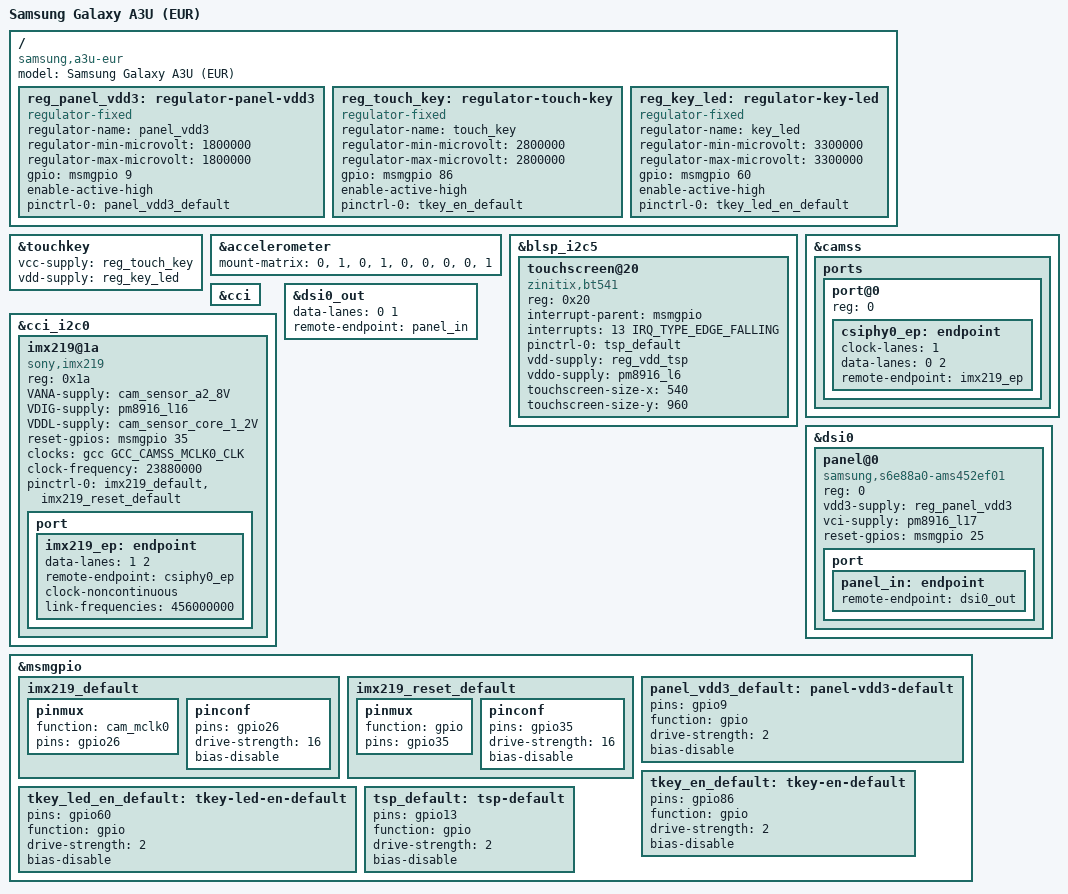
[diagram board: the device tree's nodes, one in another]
// SPDX-License-Identifier: GPL-2.0-only

/dts-v1/;

#include "msm8916-samsung-a2015-common.dtsi"

/ {
	model = "Samsung Galaxy A3U (EUR)";
	compatible = "samsung,a3u-eur", "qcom,msm8916";

	reg_panel_vdd3: regulator-panel-vdd3 {
		compatible = "regulator-fixed";
		regulator-name = "panel_vdd3";
		regulator-min-microvolt = <1800000>;
		regulator-max-microvolt = <1800000>;

		gpio = <&msmgpio 9 GPIO_ACTIVE_HIGH>;
		enable-active-high;

		pinctrl-names = "default";
		pinctrl-0 = <&panel_vdd3_default>;
	};

	reg_touch_key: regulator-touch-key {
		compatible = "regulator-fixed";
		regulator-name = "touch_key";
		regulator-min-microvolt = <2800000>;
		regulator-max-microvolt = <2800000>;

		gpio = <&msmgpio 86 GPIO_ACTIVE_HIGH>;
		enable-active-high;

		pinctrl-names = "default";
		pinctrl-0 = <&tkey_en_default>;
	};

	reg_key_led: regulator-key-led {
		compatible = "regulator-fixed";
		regulator-name = "key_led";
		regulator-min-microvolt = <3300000>;
		regulator-max-microvolt = <3300000>;

		gpio = <&msmgpio 60 GPIO_ACTIVE_HIGH>;
		enable-active-high;

		pinctrl-names = "default";
		pinctrl-0 = <&tkey_led_en_default>;
	};
};

&touchkey {
	vcc-supply = <&reg_touch_key>;
	vdd-supply = <&reg_key_led>;
};

&accelerometer {
	mount-matrix = "0", "1", "0",
		       "1", "0", "0",
		       "0", "0", "1";
};

&blsp_i2c5 {
	status = "okay";

	touchscreen@20 {
		compatible = "zinitix,bt541";
		reg = <0x20>;
		interrupt-parent = <&msmgpio>;
		interrupts = <13 IRQ_TYPE_EDGE_FALLING>;
		pinctrl-names = "default";
		pinctrl-0 = <&tsp_default>;
		vdd-supply = <&reg_vdd_tsp>;
		vddo-supply = <&pm8916_l6>;
		touchscreen-size-x = <540>;
		touchscreen-size-y = <960>;
	};
};

&camss {
	status = "okay";

	ports {
		port@0 {
			reg = <0>;
			csiphy0_ep: endpoint {
				clock-lanes = <1>;
				data-lanes = <0 2>;
				remote-endpoint = <&imx219_ep>;
			};
		};
	};
};

&cci {
	status = "okay";
};

&cci_i2c0 {
	imx219@1a {
		reg = <0x1a>;

		compatible = "sony,imx219";

		VANA-supply = <&cam_sensor_a2_8V>;
		VDIG-supply = <&pm8916_l16>;
		VDDL-supply = <&cam_sensor_core_1_2V>;

		reset-gpios = <&msmgpio 35 GPIO_ACTIVE_HIGH>;

		clocks = <&gcc GCC_CAMSS_MCLK0_CLK>;
		clock-frequency = <23880000>;

		pinctrl-names = "default";
		pinctrl-0 = <&imx219_default>, <&imx219_reset_default>;

		port {
			imx219_ep: endpoint {
				data-lanes = <1 2>;
				remote-endpoint = <&csiphy0_ep>;
				clock-noncontinuous;
				link-frequencies = /bits/ 64 <456000000>;
			};
		};
	};
};

&dsi0 {
	panel@0 {
		reg = <0>;

		compatible = "samsung,s6e88a0-ams452ef01";

		vdd3-supply = <&reg_panel_vdd3>;
		vci-supply = <&pm8916_l17>;
		reset-gpios = <&msmgpio 25 GPIO_ACTIVE_HIGH>;

		port {
			panel_in: endpoint {
				remote-endpoint = <&dsi0_out>;
			};
		};
	};
};

&dsi0_out {
	data-lanes = <0 1>;
	remote-endpoint = <&panel_in>;
};

&msmgpio {
	imx219_default: imx219_default {
		pinmux {
			function = "cam_mclk0";
			pins = "gpio26";
		};
		pinconf {
			pins = "gpio26";
			drive-strength = <16>;
			bias-disable;
		};
	};

	imx219_reset_default: imx219_reset_default {
		pinmux {
			function = "gpio";
			pins = "gpio35";
		};
		pinconf {
			pins = "gpio35";
			drive-strength = <16>;
			bias-disable;
		};
	};

	panel_vdd3_default: panel-vdd3-default {
		pins = "gpio9";
		function = "gpio";

		drive-strength = <2>;
		bias-disable;
	};

	tkey_en_default: tkey-en-default {
		pins = "gpio86";
		function = "gpio";

		drive-strength = <2>;
		bias-disable;
	};

	tkey_led_en_default: tkey-led-en-default {
		pins = "gpio60";
		function = "gpio";

		drive-strength = <2>;
		bias-disable;
	};

	tsp_default: tsp-default {
		pins = "gpio13";
		function = "gpio";

		drive-strength = <2>;
		bias-disable;
	};
};
